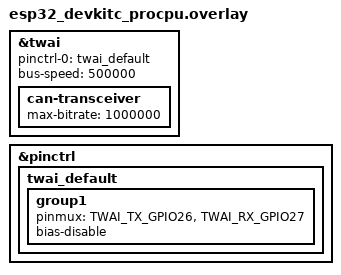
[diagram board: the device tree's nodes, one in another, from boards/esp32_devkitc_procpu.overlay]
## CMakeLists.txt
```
# SPDX-License-Identifier: Apache-2.0

cmake_minimum_required(VERSION 3.20.0)

find_package(Zephyr REQUIRED HINTS $ENV{ZEPHYR_BASE})
project(canapp)

target_sources(app PRIVATE src/main.c)
```

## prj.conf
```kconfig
CONFIG_CAN=y
# ESP32 TWAI CAN Controller for esp32_devkitc/esp32/procpu target (at least)
CONFIG_CAN_ESP32_TWAI=y

# Kvaser CAN Controller of qemu_x86_64 target
#CONFIG_CAN_KVASER_PCI=y

CONFIG_SHELL=y
CONFIG_CAN_SHELL=y
#
CONFIG_STATS=y
CONFIG_CAN_STATS=y
#
CONFIG_LOG=y
CONFIG_CAN_LOG_LEVEL_DBG=y
```

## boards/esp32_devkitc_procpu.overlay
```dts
/*
 * Copyright (c) 2025 Masanori Itoh
 *
 * SPDX-License-Identifier: Apache-2.0
 */

&twai {
        status = "okay";
        pinctrl-0 = <&twai_default>;
        pinctrl-names = "default";
        bus-speed = <500000>;

        can-transceiver {
            max-bitrate = <1000000>;
        };

};

#include <zephyr/dt-bindings/pinctrl/esp-pinctrl-common.h>
#include <dt-bindings/pinctrl/esp32-pinctrl.h>
#include <zephyr/dt-bindings/pinctrl/esp32-gpio-sigmap.h>

&pinctrl {
        twai_default: twai_default {
                group1 {
                        pinmux = <TWAI_TX_GPIO26>,
                                 <TWAI_RX_GPIO27>;
                        bias-disable;
                };
        };
};
```

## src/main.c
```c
/*
 * Copyright (c) Masanori Itoh
 *
 * SPDX-License-Identifier: Apache-2.0
 */

#include <stdio.h>

#include <zephyr/logging/log.h>
LOG_MODULE_REGISTER(sodev_canapp, LOG_LEVEL_DBG);
  
#include <zephyr/kernel.h>

#include <zephyr/sys/printk.h>


int main(void)
{
  printf("Hello World! %s\n", CONFIG_BOARD_TARGET);
  return 0;
}
```
